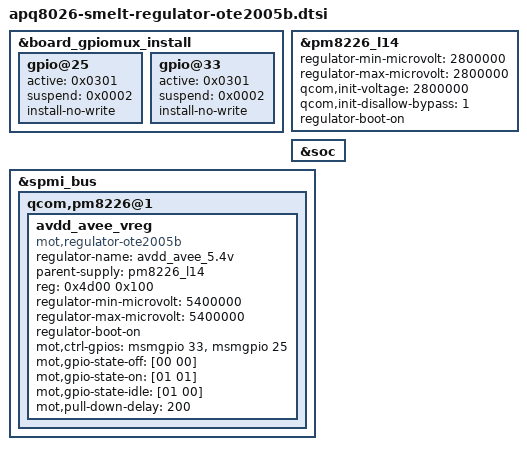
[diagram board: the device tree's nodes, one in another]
/* Copyright (c) 2014, The Linux Foundation. All rights reserved.
 *
 * This program is free software; you can redistribute it and/or modify
 * it under the terms of the GNU General Public License version 2 and
 * only version 2 as published by the Free Software Foundation.
 *
 * This program is distributed in the hope that it will be useful,
 * but WITHOUT ANY WARRANTY; without even the implied warranty of
 * MERCHANTABILITY or FITNESS FOR A PARTICULAR PURPOSE.  See the
 * GNU General Public License for more details.
 */

&board_gpiomux_install {
	gpio@25 {
		active  = <0x0301>; /* FUNC_GPIO, DRV_8MA, PULL_NONE, OUT_HIGH */
		suspend = <0x0002>; /* FUNC_GPIO, DRV_2MA, PULL_NONE, OUT_LOW */
		install-no-write;
	};
	gpio@33 {
		active  = <0x0301>; /* FUNC_GPIO, DRV_8MA, PULL_NONE, OUT_HIGH */
		suspend = <0x0002>; /* FUNC_GPIO, DRV_2MA, PULL_NONE, OUT_LOW */
		install-no-write;
	};
};

&pm8226_l14 {
	regulator-min-microvolt = <2800000>;
	regulator-max-microvolt = <2800000>;
	qcom,init-voltage = <2800000>;
	qcom,init-disallow-bypass = <1>;
	regulator-boot-on;
};

&soc {
	/delete-node/ avdd_avee_vreg;
};

&spmi_bus {
	qcom,pm8226@1 {
		avdd_avee_vreg: avdd_avee_vreg {
			compatible = "mot,regulator-ote2005b";
			regulator-name = "avdd_avee_5.4v";
			parent-supply = <&pm8226_l14>;
			reg = <0x4d00 0x100>;
			regulator-min-microvolt = <5400000>;
			regulator-max-microvolt = <5400000>;
			regulator-boot-on;
			mot,ctrl-gpios = <&msmgpio 33 0x0>,
					 <&msmgpio 25 0x0>;
			mot,gpio-state-off = [00 00];
			mot,gpio-state-on  = [01 01];
			mot,gpio-state-idle= [01 00];
			mot,pull-down-delay = <200>;
		};
	};
};
